AUTOSAR XML (schema 4-2-1)
package /MICROSAR/NvM_swc/DataTypes
  impl type NvM_RequestResultType: compu {0=NVM_REQ_OK, 1=NVM_REQ_NOT_OK, 2=NVM_REQ_PENDING, 3=NVM_REQ_INTEGRITY_FAILED, 4=NVM_REQ_BLOCK_SKIPPED, 5=NVM_REQ_NV_INVALIDATED, 6=NVM_REQ_CANCELED, 7=NVM_REQ_REDUNDANCY_FAILED, 8=NVM_REQ_RESTORED_FROM_ROM}, implementation-data-type=uint8
  impl type NvM_BlockIdType: range raw 1..32767, implementation-data-type=uint16
  impl type NvM_ServiceIdType: compu {6=NVM_READ_BLOCK, 7=NVM_WRITE_BLOCK, 8=NVM_RESTORE_BLOCK_DEFAULTS, 9=NVM_ERASE_BLOCK, 11=NVM_INVALIDATE_NV_BLOCK, 12=NVM_READ_ALL}, implementation-data-type=uint8
package /MICROSAR/NvM_swc/Interfaces
  4 x client server interface, all with is-service=true, service-kind=NON-VOLATILE-RAM-MANAGER:
    NvMAdministration
      operation SetBlockProtection: possible-error=NvMAdministration/E_NOT_OK
        arg ProtectionEnabled: type=boolean, direction=IN
      error E_NOT_OK: error-code=1
    NvMService_AC3_SRBS
      6 x operation, all with possible-error=NvMService_AC3_SRBS/E_NOT_OK:
        GetErrorStatus
          arg ErrorStatus: type=NvM_RequestResultType, direction=OUT
        SetRamBlockStatus
          arg RamBlockStatus: type=boolean, direction=IN
        ReadBlock
          arg DstPtr: type=dtRef_VOID, direction=IN
        WriteBlock
          arg SrcPtr: type=dtRef_const_VOID, direction=IN
        InvalidateNvBlock
        EraseBlock
      error E_NOT_OK: error-code=1
    NvMService_AC3_SRBS_Defs
      7 x operation, all with possible-error=NvMService_AC3_SRBS_Defs/E_NOT_OK:
        GetErrorStatus
          arg ErrorStatus: type=NvM_RequestResultType, direction=OUT
        SetRamBlockStatus
          arg RamBlockStatus: type=boolean, direction=IN
        ReadBlock
          arg DstPtr: type=dtRef_VOID, direction=IN
        WriteBlock
          arg SrcPtr: type=dtRef_const_VOID, direction=IN
        RestoreBlockDefaults
          arg DstPtr: type=dtRef_VOID, direction=IN
        InvalidateNvBlock
        EraseBlock
      error E_NOT_OK: error-code=1
    NvMNotifyJobFinished
      operation JobFinished
        arg ServiceId: type=NvM_ServiceIdType, direction=IN
        arg JobResult: type=NvM_RequestResultType, direction=IN
package /MICROSAR/NvM_swc/ComponentTypes
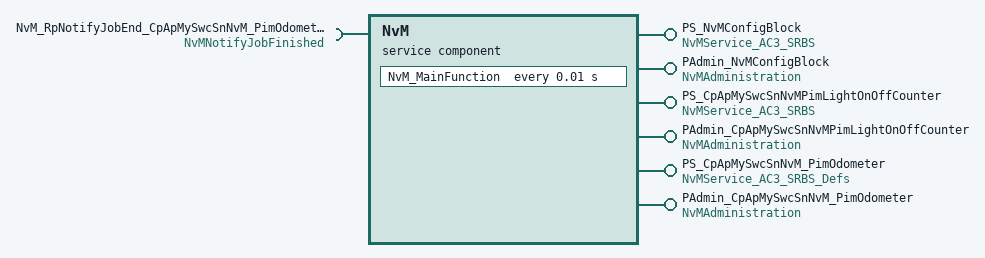
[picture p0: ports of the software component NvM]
  service sw component type NvM: category=SERVICE_COMPONENT
    6 x provide port:
      PS_NvMConfigBlock: provided-interface=NvMService_AC3_SRBS
      PAdmin_NvMConfigBlock: provided-interface=NvMAdministration
      PS_CpApMySwcSnNvMPimLightOnOffCounter: provided-interface=NvMService_AC3_SRBS
      PAdmin_CpApMySwcSnNvMPimLightOnOffCounter: provided-interface=NvMAdministration
      PS_CpApMySwcSnNvM_PimOdometer: provided-interface=NvMService_AC3_SRBS_Defs
      PAdmin_CpApMySwcSnNvM_PimOdometer: provided-interface=NvMAdministration
    require port NvM_RpNotifyJobEnd_CpApMySwcSnNvM_PimOdometer: required-interface=NvMNotifyJobFinished
    behavior NvMInternalBehavior: handle-termination-and-restart=NO-SUPPORT
      timing event Timer_NvM_MainFunction: start-on-event=NvM_MainFunction, period=0.01
      22 x operation invoked event:
        OpEventGetErrorStatus_GetErrorStatus_PS_NvMConfigBlock: start-on-event=GetErrorStatus, operation=PS_NvMConfigBlock.GetErrorStatus
        OpEventSetRamBlockStatus_SetRamBlockStatus_PS_NvMConfigBlock: start-on-event=SetRamBlockStatus, operation=PS_NvMConfigBlock.SetRamBlockStatus
        OpEventReadBlock_ReadBlock_PS_NvMConfigBlock: start-on-event=ReadBlock, operation=PS_NvMConfigBlock.ReadBlock
        OpEventWriteBlock_WriteBlock_PS_NvMConfigBlock: start-on-event=WriteBlock, operation=PS_NvMConfigBlock.WriteBlock
        OpEventInvalidateNvBlock_InvalidateNvBlock_PS_NvMConfigBlock: start-on-event=InvalidateNvBlock, operation=PS_NvMConfigBlock.InvalidateNvBlock
        OpEventEraseBlock_EraseBlock_PS_NvMConfigBlock: start-on-event=EraseBlock, operation=PS_NvMConfigBlock.EraseBlock
        OpEventSetBlockProtection_SetBlockProtection_PAdmin_NvMConfigBlock: start-on-event=SetBlockProtection, operation=PAdmin_NvMConfigBlock.SetBlockProtection
        OpEventGetErrorStatus_GetErrorStatus_PS_CpApMySwcSnNvMPimLightOnOffCounter: start-on-event=GetErrorStatus, operation=PS_CpApMySwcSnNvMPimLightOnOffCounter.GetErrorStatus
        OpEventSetRamBlockStatus_SetRamBlockStatus_PS_CpApMySwcSnNvMPimLightOnOffCounter: start-on-event=SetRamBlockStatus, operation=PS_CpApMySwcSnNvMPimLightOnOffCounter.SetRamBlockStatus
        OpEventReadBlock_ReadBlock_PS_CpApMySwcSnNvMPimLightOnOffCounter: start-on-event=ReadBlock, operation=PS_CpApMySwcSnNvMPimLightOnOffCounter.ReadBlock
        OpEventWriteBlock_WriteBlock_PS_CpApMySwcSnNvMPimLightOnOffCounter: start-on-event=WriteBlock, operation=PS_CpApMySwcSnNvMPimLightOnOffCounter.WriteBlock
        OpEventInvalidateNvBlock_InvalidateNvBlock_PS_CpApMySwcSnNvMPimLightOnOffCounter: start-on-event=InvalidateNvBlock, operation=PS_CpApMySwcSnNvMPimLightOnOffCounter.InvalidateNvBlock
        OpEventEraseBlock_EraseBlock_PS_CpApMySwcSnNvMPimLightOnOffCounter: start-on-event=EraseBlock, operation=PS_CpApMySwcSnNvMPimLightOnOffCounter.EraseBlock
        OpEventSetBlockProtection_SetBlockProtection_PAdmin_CpApMySwcSnNvMPimLightOnOffCounter: start-on-event=SetBlockProtection, operation=PAdmin_CpApMySwcSnNvMPimLightOnOffCounter.SetBlockProtection
        OpEventGetErrorStatus_GetErrorStatus_PS_CpApMySwcSnNvM_PimOdometer: start-on-event=GetErrorStatus, operation=PS_CpApMySwcSnNvM_PimOdometer.GetErrorStatus
        OpEventSetRamBlockStatus_SetRamBlockStatus_PS_CpApMySwcSnNvM_PimOdometer: start-on-event=SetRamBlockStatus, operation=PS_CpApMySwcSnNvM_PimOdometer.SetRamBlockStatus
        OpEventReadBlock_ReadBlock_PS_CpApMySwcSnNvM_PimOdometer: start-on-event=ReadBlock, operation=PS_CpApMySwcSnNvM_PimOdometer.ReadBlock
        OpEventWriteBlock_WriteBlock_PS_CpApMySwcSnNvM_PimOdometer: start-on-event=WriteBlock, operation=PS_CpApMySwcSnNvM_PimOdometer.WriteBlock
        OpEventRestoreBlockDefaults_RestoreBlockDefaults_PS_CpApMySwcSnNvM_PimOdometer: start-on-event=RestoreBlockDefaults, operation=PS_CpApMySwcSnNvM_PimOdometer.RestoreBlockDefaults
        OpEventInvalidateNvBlock_InvalidateNvBlock_PS_CpApMySwcSnNvM_PimOdometer: start-on-event=InvalidateNvBlock, operation=PS_CpApMySwcSnNvM_PimOdometer.InvalidateNvBlock
        OpEventEraseBlock_EraseBlock_PS_CpApMySwcSnNvM_PimOdometer: start-on-event=EraseBlock, operation=PS_CpApMySwcSnNvM_PimOdometer.EraseBlock
        OpEventSetBlockProtection_SetBlockProtection_PAdmin_CpApMySwcSnNvM_PimOdometer: start-on-event=SetBlockProtection, operation=PAdmin_CpApMySwcSnNvM_PimOdometer.SetBlockProtection
      port-api-options:
        {enable-take-address=true, indirect-api=false, port-defined-argument-value{value=1, value-type=NvM_BlockIdType}, port=PS_NvMConfigBlock}
        {enable-take-address=true, indirect-api=false, port-defined-argument-value{value=1, value-type=NvM_BlockIdType}, port=PAdmin_NvMConfigBlock}
        enable-take-address=true, indirect-api=false, port=NvM_RpNotifyJobEnd_CpApMySwcSnNvM_PimOdometer
        {enable-take-address=true, indirect-api=false, port-defined-argument-value{value=2, value-type=NvM_BlockIdType}, port=PS_CpApMySwcSnNvMPimLightOnOffCounter}
        {enable-take-address=true, indirect-api=false, port-defined-argument-value{value=2, value-type=NvM_BlockIdType}, port=PAdmin_CpApMySwcSnNvMPimLightOnOffCounter}
        {enable-take-address=true, indirect-api=false, port-defined-argument-value{value=13, value-type=NvM_BlockIdType}, port=PS_CpApMySwcSnNvM_PimOdometer}
        {enable-take-address=true, indirect-api=false, port-defined-argument-value{value=13, value-type=NvM_BlockIdType}, port=PAdmin_CpApMySwcSnNvM_PimOdometer}
      9 x runnable:
        NvM_MainFunction
          sync call OpServerCallNvM_MainFunction_JobFinished_NvM_RpNotifyJobEnd_CpApMySwcSnNvM_PimOdometer: operation=NvM_RpNotifyJobEnd_CpApMySwcSnNvM_PimOdometer.JobFinished, timeout=0
        GetErrorStatus: can-be-invoked-concurrently=true, symbol=NvM_GetErrorStatus
        SetRamBlockStatus: can-be-invoked-concurrently=true, symbol=NvM_SetRamBlockStatus
        ReadBlock: can-be-invoked-concurrently=true, symbol=NvM_ReadBlock
        WriteBlock: can-be-invoked-concurrently=true, symbol=NvM_WriteBlock
        InvalidateNvBlock: can-be-invoked-concurrently=true, symbol=NvM_InvalidateNvBlock
        EraseBlock: can-be-invoked-concurrently=true, symbol=NvM_EraseNvBlock
        SetBlockProtection: can-be-invoked-concurrently=true, symbol=NvM_SetBlockProtection
        RestoreBlockDefaults: can-be-invoked-concurrently=true, symbol=NvM_RestoreBlockDefaults
  swc implementation NvMImplementation: programming-language=C, behavior=NvMInternalBehavior
